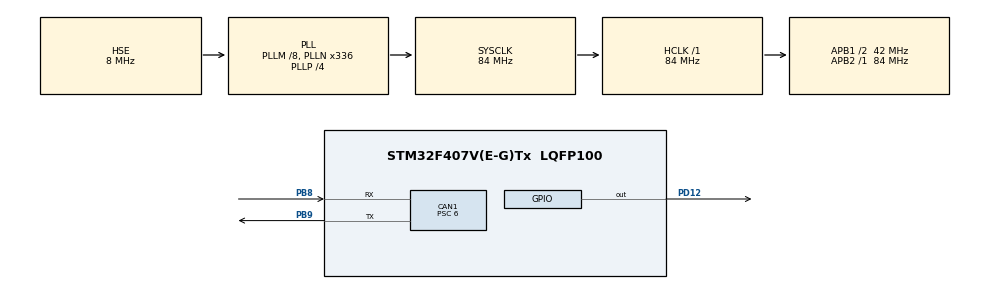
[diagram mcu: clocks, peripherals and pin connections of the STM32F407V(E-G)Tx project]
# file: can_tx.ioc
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CAN1.BS1=CAN_BS1_11TQ
CAN1.BS2=CAN_BS2_2TQ
CAN1.CalculateBaudRate=500000
CAN1.CalculateTimeBit=2000
CAN1.CalculateTimeQuantum=142.85714285714286
CAN1.NART=ENABLE
CAN1.Prescaler=6
Mcu.Family=STM32F4
Mcu.Name=STM32F407V(E-G)Tx
Mcu.Package=LQFP100
NVIC.PriorityGroup=NVIC_PRIORITYGROUP_0
PB8.Mode=CAN_Activate
PB8.Signal=CAN1_RX
PB9.Mode=CAN_Activate
PB9.Signal=CAN1_TX
PD12.Signal=GPIO_Output
PH0-OSC_IN.Mode=HSE-External-Oscillator
PH0-OSC_IN.Signal=RCC_OSC_IN
PH1-OSC_OUT.Mode=HSE-External-Oscillator
PH1-OSC_OUT.Signal=RCC_OSC_OUT
ProjectManager.HeapSize=0x200
ProjectManager.StackSize=0x400
ProjectManager.TargetToolchain=STM32CubeIDE
RCC.48MHZClocksFreq_Value=48000000
RCC.AHBFreq_Value=84000000
RCC.APB1CLKDivider=RCC_HCLK_DIV2
RCC.APB1Freq_Value=42000000
RCC.APB1TimFreq_Value=84000000
RCC.APB2Freq_Value=84000000
RCC.APB2TimFreq_Value=84000000
RCC.CortexFreq_Value=84000000
RCC.HCLKFreq_Value=84000000
RCC.HSE_VALUE=8000000
RCC.HSI_VALUE=16000000
RCC.LSE_VALUE=32768
RCC.PLLM=8
RCC.PLLN=336
RCC.PLLP=RCC_PLLP_DIV4
RCC.PLLQ=7
RCC.PLLSourceVirtual=RCC_PLLSOURCE_HSE
RCC.SYSCLKFreq_VALUE=84000000
RCC.SYSCLKSource=RCC_SYSCLKSOURCE_PLLCLK
RCC.VCOOutputFreq_Value=336000000
board=STM32F407G-DISC1

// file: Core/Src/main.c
/* USER CODE BEGIN Header */
/**
  ******************************************************************************
  * @file           : main.c
  * @brief          : Main program body
  ******************************************************************************
  * @attention
  *
  * Copyright (c) 2026 STMicroelectronics.
  * All rights reserved.
  *
  * This software is licensed under terms that can be found in the LICENSE file
  * in the root directory of this software component.
  * If no LICENSE file comes with this software, it is provided AS-IS.
  *
  ******************************************************************************
  */
/* USER CODE END Header */
#include "main.h"

CAN_HandleTypeDef hcan1;

/* USER CODE BEGIN PV */
CAN_TxHeaderTypeDef TxHeader;
uint8_t TxData[8];
uint32_t TxMailbox;

CAN_FilterTypeDef CAN_Filter;
/* USER CODE END PV */

void SystemClock_Config(void);
static void MX_GPIO_Init(void);
static void MX_CAN1_Init(void);

int main(void)
{

  /* MCU Configuration--------------------------------------------------------*/

  /* Reset of all peripherals, Initializes the Flash interface and the Systick. */
  HAL_Init();

  /* Configure the system clock */
  SystemClock_Config();

  /* Initialize all configured peripherals */
  MX_GPIO_Init();
  MX_CAN1_Init();
  /* USER CODE BEGIN 2 */
  CAN_Filter.FilterBank = 0;
  CAN_Filter.FilterMode = CAN_FILTERMODE_IDMASK;
  CAN_Filter.FilterScale = CAN_FILTERSCALE_32BIT;

  CAN_Filter.FilterIdHigh = 0x0000;
  CAN_Filter.FilterIdLow = 0x0000;
  CAN_Filter.FilterMaskIdHigh = 0x0000;
  CAN_Filter.FilterMaskIdLow = 0x0000;

  CAN_Filter.FilterFIFOAssignment = CAN_FILTER_FIFO0;
  CAN_Filter.FilterActivation = ENABLE;

  if (HAL_CAN_ConfigFilter(&hcan1, &CAN_Filter) != HAL_OK)
  {
      Error_Handler();
  }

  /* Start CAN */
  if (HAL_CAN_Start(&hcan1) != HAL_OK)
  {
      Error_Handler();
  }

  /* Configure Tx Header */
  TxHeader.StdId = 0x321;      // CAN ID
  TxHeader.ExtId = 0;
  TxHeader.IDE = CAN_ID_STD;
  TxHeader.RTR = CAN_RTR_DATA;
  TxHeader.DLC = 5;            // HELLO = 5 bytes
  TxHeader.TransmitGlobalTime = DISABLE;
  /* USER CODE END 2 */

  /* Infinite loop */
  /* USER CODE BEGIN WHILE */
  while (1)
  {
	  TxData[0] = 'H';
	      TxData[1] = 'E';
	      TxData[2] = 'L';
	      TxData[3] = 'L';
	      TxData[4] = 'O';

	      if (HAL_CAN_AddTxMessage(&hcan1,
	                               &TxHeader,
	                               TxData,
	                               &TxMailbox) == HAL_OK)
	      {
	          HAL_GPIO_TogglePin(GPIOD, GPIO_PIN_12);   // blink LED
	      }

	      HAL_Delay(1000);
    /* USER CODE END WHILE */

  }
}

void SystemClock_Config(void)
{
  RCC_OscInitTypeDef RCC_OscInitStruct = {0};
  RCC_ClkInitTypeDef RCC_ClkInitStruct = {0};

  /** Configure the main internal regulator output voltage
  */
  __HAL_RCC_PWR_CLK_ENABLE();
  __HAL_PWR_VOLTAGESCALING_CONFIG(PWR_REGULATOR_VOLTAGE_SCALE1);

  /** Initializes the RCC Oscillators according to the specified parameters
  * in the RCC_OscInitTypeDef structure.
  */
  RCC_OscInitStruct.OscillatorType = RCC_OSCILLATORTYPE_HSE;
  RCC_OscInitStruct.HSEState = RCC_HSE_ON;
  RCC_OscInitStruct.PLL.PLLState = RCC_PLL_ON;
  RCC_OscInitStruct.PLL.PLLSource = RCC_PLLSOURCE_HSE;
  RCC_OscInitStruct.PLL.PLLM = 8;
  RCC_OscInitStruct.PLL.PLLN = 336;
  RCC_OscInitStruct.PLL.PLLP = RCC_PLLP_DIV4;
  RCC_OscInitStruct.PLL.PLLQ = 7;
  if (HAL_RCC_OscConfig(&RCC_OscInitStruct) != HAL_OK)
  {
    Error_Handler();
  }

  /** Initializes the CPU, AHB and APB buses clocks
  */
  RCC_ClkInitStruct.ClockType = RCC_CLOCKTYPE_HCLK|RCC_CLOCKTYPE_SYSCLK
                              |RCC_CLOCKTYPE_PCLK1|RCC_CLOCKTYPE_PCLK2;
  RCC_ClkInitStruct.SYSCLKSource = RCC_SYSCLKSOURCE_PLLCLK;
  RCC_ClkInitStruct.AHBCLKDivider = RCC_SYSCLK_DIV1;
  RCC_ClkInitStruct.APB1CLKDivider = RCC_HCLK_DIV2;
  RCC_ClkInitStruct.APB2CLKDivider = RCC_HCLK_DIV1;

  if (HAL_RCC_ClockConfig(&RCC_ClkInitStruct, FLASH_LATENCY_2) != HAL_OK)
  {
    Error_Handler();
  }
}

static void MX_CAN1_Init(void)
{

  hcan1.Instance = CAN1;
  hcan1.Init.Prescaler = 6;
  hcan1.Init.Mode = CAN_MODE_NORMAL;
  hcan1.Init.SyncJumpWidth = CAN_SJW_1TQ;
  hcan1.Init.TimeSeg1 = CAN_BS1_11TQ;
  hcan1.Init.TimeSeg2 = CAN_BS2_2TQ;
  hcan1.Init.TimeTriggeredMode = DISABLE;
  hcan1.Init.AutoBusOff = DISABLE;
  hcan1.Init.AutoWakeUp = DISABLE;
  hcan1.Init.AutoRetransmission = ENABLE;
  hcan1.Init.ReceiveFifoLocked = DISABLE;
  hcan1.Init.TransmitFifoPriority = DISABLE;
  if (HAL_CAN_Init(&hcan1) != HAL_OK)
  {
    Error_Handler();
  }

}

static void MX_GPIO_Init(void)
{
  GPIO_InitTypeDef GPIO_InitStruct = {0};

  /* GPIO Ports Clock Enable */
  __HAL_RCC_GPIOH_CLK_ENABLE();
  __HAL_RCC_GPIOD_CLK_ENABLE();
  __HAL_RCC_GPIOB_CLK_ENABLE();

  /*Configure GPIO pin Output Level */
  HAL_GPIO_WritePin(GPIOD, GPIO_PIN_12, GPIO_PIN_RESET);

  /*Configure GPIO pin : PD12 */
  GPIO_InitStruct.Pin = GPIO_PIN_12;
  GPIO_InitStruct.Mode = GPIO_MODE_OUTPUT_PP;
  GPIO_InitStruct.Pull = GPIO_NOPULL;
  GPIO_InitStruct.Speed = GPIO_SPEED_FREQ_LOW;
  HAL_GPIO_Init(GPIOD, &GPIO_InitStruct);

}

void Error_Handler(void)
{
  __disable_irq();
  while (1)
  {
  }
}
